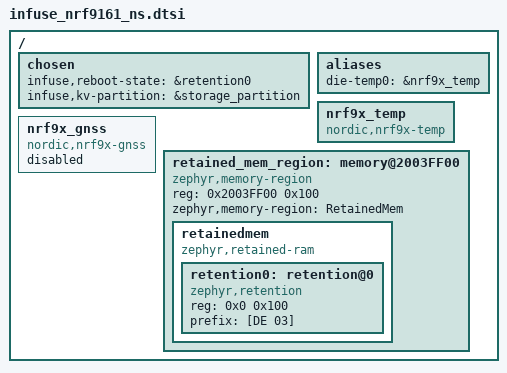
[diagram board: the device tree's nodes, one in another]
/*
 * Copyright (c) 2025 Embeint Holdings Pty Ltd
 * SPDX-License-Identifier: FSL-1.1-ALv2
 */

/ {
	chosen {
		infuse,reboot-state = &retention0;
		infuse,kv-partition = &storage_partition;
	};

	aliases {
		die-temp0 = &nrf9x_temp;
	};

	nrf9x_temp: nrf9x_temp {
		compatible = "nordic,nrf9x-temp";
	};

	nrf9x_gnss: nrf9x_gnss {
		compatible = "nordic,nrf9x-gnss";
		status = "disabled";
	};

	/* End of application SRAM */
	retained_mem_region: memory@2003FF00 {
		compatible = "zephyr,memory-region", "mmio-sram";
		reg = <0x2003FF00 0x100>;
		zephyr,memory-region = "RetainedMem";
		status = "okay";

		retainedmem {
			compatible = "zephyr,retained-ram";
			status = "okay";
			#address-cells = <1>;
			#size-cells = <1>;

			retention0: retention@0 {
				compatible = "zephyr,retention";
				status = "okay";
				reg = <0x0 0x100>;
				prefix = [DE 03];
			};
		};
	};
};

#include "modem_shmem.dtsi"
